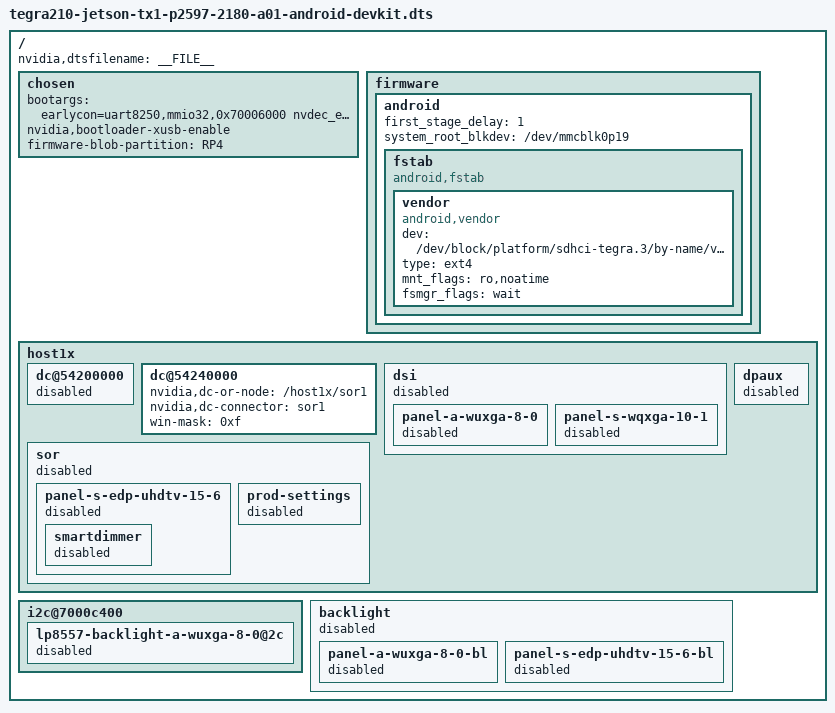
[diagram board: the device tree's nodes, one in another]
/*
 * Copyright (c) 2014-2018, NVIDIA CORPORATION. All rights reserved.
 *
 * This program is free software; you can redistribute it and/or modify
 * it under the terms of the GNU General Public License as published by
 * the Free Software Foundation; version 2 of the License.
 *
 * This program is distributed in the hope that it will be useful, but WITHOUT
 * ANY WARRANTY; without even the implied warranty of MERCHANTABILITY or
 * FITNESS FOR A PARTICULAR PURPOSE.  See the GNU General Public License for
 * more details.
 *
 */

#include "tegra210-jetson-cv-p2597-2180-a00.dts"

/ {
	nvidia,dtsfilename = __FILE__;

	chosen {
		bootargs = "earlycon=uart8250,mmio32,0x70006000 nvdec_enabled=0";
		nvidia,bootloader-xusb-enable;
		firmware-blob-partition = "RP4";
	};

	firmware {
		android {
			first_stage_delay = "1";
			system_root_blkdev = "/dev/mmcblk0p19";
			fstab {
				compatible = "android,fstab";
				vendor {
					compatible = "android,vendor";
					dev = "/dev/block/platform/sdhci-tegra.3/by-name/vendor";
					type = "ext4";
					mnt_flags = "ro,noatime";
					fsmgr_flags = "wait";
				};
			};
		};
	};

	host1x {
		dc@54200000 {
			status = "disabled";
		};

		dc@54240000 {
			nvidia,dc-or-node = "/host1x/sor1";
			nvidia,dc-connector = <&sor1>;
			win-mask = <0xf>;
		};

		dsi {
			status = "disabled";
			panel-a-wuxga-8-0 {
				status = "disabled";
			};
			panel-s-wqxga-10-1 {
				status = "disabled";
			};
		};

		sor {
			status = "disabled";
			panel-s-edp-uhdtv-15-6 {
				status = "disabled";
				smartdimmer {
					status = "disabled";
				};
			};
			prod-settings {
				status = "disabled";
			};
		};

		dpaux {
			status = "disabled";
		};
	};

	i2c@7000c400 {
		lp8557-backlight-a-wuxga-8-0@2c {
			status = "disabled";
		};
	};

	backlight {
		status = "disabled";
		panel-a-wuxga-8-0-bl {
			status = "disabled";
		};
		panel-s-edp-uhdtv-15-6-bl {
			status = "disabled";
		};
	};
};
